# PIC32CX2051MTSH128S1 register map
Vendor: Microchip Technology; Series: PIC32CXMTSH; File version: 0
CPU: CM4 r0p1, little endian, MPU, FPU, 4 interrupt priority bits, 96 interrupts
Registers are 32-bit, read-write, reset 0x0 unless marked. A register's access mark holds for its fields unless they carry their own. Offsets are from the block's base; [hi:lo] are bit positions; {n}, {i} and the like mark numbered series.

## SCB — System Control Block
Base 0xE000ED00
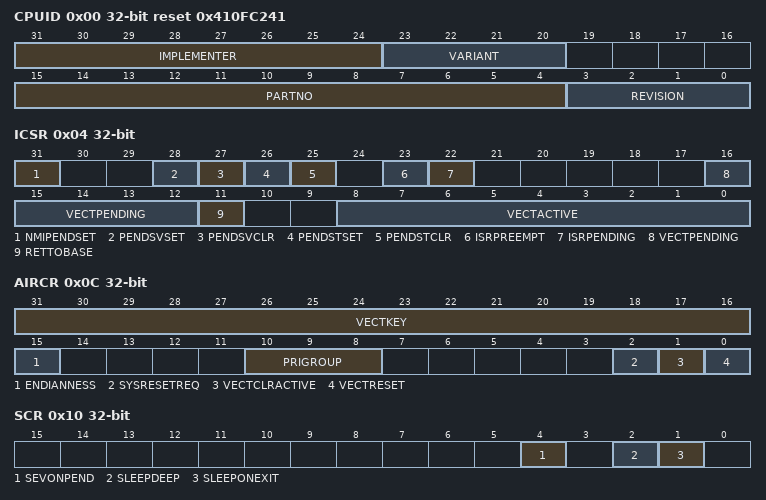
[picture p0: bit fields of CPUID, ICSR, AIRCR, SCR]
0x00 CPUID ro reset 0x410FC241 — CPUID Base Register
  [31:24] IMPLEMENTER — Indicates implementer: 0x41 = ARM
  [23:20] VARIANT — Indicates processor revision: 0x0 = Revision 0
  [15:4] PARTNO — Indicates part number: 0xC24 = Cortex-M4
  [3:0] REVISION — Indicates patch release: 0x1 = Patch 1
0x04 ICSR — Interrupt Control and State Register
  [31] NMIPENDSET — On writes, makes the NMI exception active. On reads, indicates the state of the exception
    0=On writes, has no effect. On reads, NMI is inactive; 1=On writes, make the NMI exception active. On reads, NMI is active
  [28] PENDSVSET — On writes, sets the PendSV exception as pending. On reads, indicates the current state of the exception
    0=On writes, has no effect. On reads, PendSV is not pending; 1=On writes, make PendSV exception pending. On reads, PendSV is pending
  [27] PENDSVCLR — Removes the pending status of the PendSV exception
    0=No effect; 1=Remove pending status
  [26] PENDSTSET — On writes, sets the SysTick exception as pending. On reads, indicates the current state of the exception
    0=On writes, has no effect. On reads, SysTick is not pending; 1=On writes, make SysTick exception pending. On reads, SysTick is pending
  [25] PENDSTCLR — Removes the pending status of the SysTick exception
    0=No effect; 1=Remove pending status
  [23] ISRPREEMPT — Indicates whether a pending exception will be serviced on exit from debug halt state
    0=Will not service; 1=Will service a pending exception
  [22] ISRPENDING — Indicates whether an external interrupt, generated by the NVIC, is pending
  [16:12] VECTPENDING — The exception number of the highest priority pending and enabled interrupt
  [11] RETTOBASE — In Handler mode, indicates whether there is an active exception other than the exception indicated by the current value of the IPSR
    0=There is an active exception other than the exception shown by IPSR; 1=There is no active exception other than any exception shown by IPSR
  [8:0] VECTACTIVE — The exception number of the current executing exception
0x08 VTOR — Vector Table Offset Register
  [31:7] TBLOFF — Bits[31:7] of the vector table address
0x0C AIRCR — Application Interrupt and Reset Control Register
  [31:16] VECTKEY — Vector key
  [15] ENDIANNESS — Indicates the memory system endianness
    0=Little-endian; 1=Big-endian
  [10:8] PRIGROUP — Priority grouping, indicates the binary point position
  [2] SYSRESETREQ — System Reset Request
    0=Do not request a reset; 1=Request reset
  [1] VECTCLRACTIVE — Writing 1 to this bit clears all active state information for fixed and configurable exceptions
  [0] VECTRESET — Writing 1 to this bit causes a local system reset
0x10 SCR — System Control Register
  [4] SEVONPEND — Determines whether an interrupt transition from inactive state to pending state is a wakeup event
    0=Transitions from inactive to pending are not wakeup events; 1=Transitions from inactive to pending are wakeup events
  [2] SLEEPDEEP — Provides a qualifying hint indicating that waking from sleep might take longer
    0=Selected sleep state is not deep sleep; 1=Selected sleep state is deep sleep
  [1] SLEEPONEXIT — Determines whether, on an exit from an ISR that returns to the base level of execution priority, the processor enters a sleep state
    0=Do not enter sleep state; 1=Enter sleep state
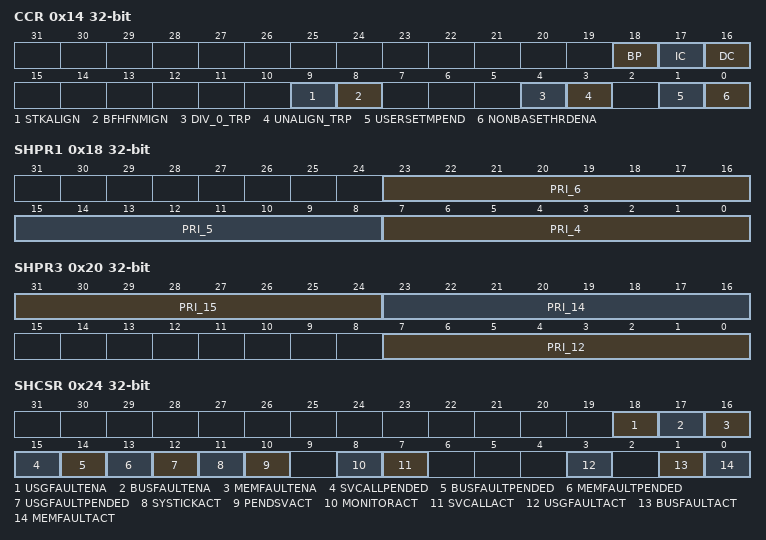
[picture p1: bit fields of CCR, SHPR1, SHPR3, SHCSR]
0x14 CCR — Configuration and Control Register
  [18] BP — Branch prediction enable bit
  [17] IC — Instruction cache enable bit
  [16] DC — Cache enable bit
  [9] STKALIGN — Indicates stack alignment on exception entry
    0=4-byte aligned; 1=8-byte aligned
  [8] BFHFNMIGN — Enables handlers with priority -1 or -2 to ignore data BusFaults caused by load and store instructions.
    0=data bus faults caused by load and store instructions cause a lock-up; 1=handlers running at priority -1 and -2 ignore data bus faults caused by load and store instructions
  [4] DIV_0_TRP — Enables faulting or halting when the processor executes an SDIV or UDIV instruction with a divisor of 0
    0=do not trap divide by 0; 1=trap divide by 0
  [3] UNALIGN_TRP — Enables unaligned access traps
    0=do not trap unaligned halfword and word accesses; 1=trap unaligned halfword and word accesses
  [1] USERSETMPEND — Enables unprivileged software access to the STIR
    0=disable; 1=enable
  [0] NONBASETHRDENA
    0=processor can enter Thread mode only when no exception is active; 1=processor can enter Thread mode from any level under the control of an EXC_RETURN value
0x18 SHPR1 — System Handler Priority Register 1
  [23:16] PRI_6 — Priority of system handler 6, UsageFault
  [15:8] PRI_5 — Priority of system handler 5, BusFault
  [7:0] PRI_4 — Priority of system handler 4, MemManage
0x1C SHPR2 — System Handler Priority Register 2
  [31:24] PRI_11 — Priority of system handler 11, SVCall
0x20 SHPR3 — System Handler Priority Register 3
  [31:24] PRI_15 — Priority of system handler 15, SysTick exception
  [23:16] PRI_14 — Priority of system handler 14, PendSV
  [7:0] PRI_12 — Priority of system handler 12, SysTick
0x24 SHCSR — System Handler Control and State Register
  [18] USGFAULTENA — UsageFault enable
    0=Disable UsageFault; 1=Enable UsageFault
  [17] BUSFAULTENA — BusFault enable
    0=Disable BusFault; 1=Enable BusFault
  [16] MEMFAULTENA — MemManage fault enable
    0=Disable MemManage fault; 1=Enable MemManage fault
  [15] SVCALLPENDED — SVCall pending
    0=SVCall is not pending; 1=SVCall is pending
  [14] BUSFAULTPENDED — BusFault pending
    0=BusFault is not pending; 1=BusFault is pending
  [13] MEMFAULTPENDED — MemManage fault pending
    0=MemManage is not pending; 1=MemManage is pending
  [12] USGFAULTPENDED — UsageFault pending
    0=UsageFault is not pending; 1=UsageFault is pending
  [11] SYSTICKACT — SysTick active
    0=SysTick is not active; 1=SysTick is active
  [10] PENDSVACT — PendSV active
    0=PendSV is not active; 1=PendSV is active
  [8] MONITORACT — Monitor active
    0=Monitor is not active; 1=Monitor is active
  [7] SVCALLACT — SVCall active
    0=SVCall is not active; 1=SVCall is active
  [3] USGFAULTACT — UsageFault active
    0=UsageFault is not active; 1=UsageFault is active
  [1] BUSFAULTACT — BusFault active
    0=BusFault is not active; 1=BusFault is active
  [0] MEMFAULTACT — MemManage fault active
    0=MemManage is not active; 1=MemManage is active
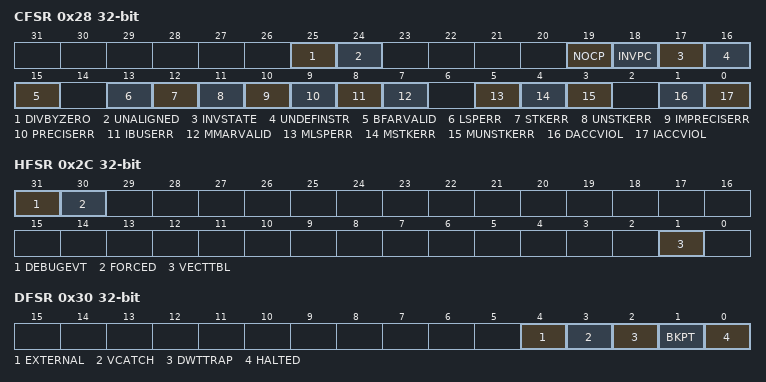
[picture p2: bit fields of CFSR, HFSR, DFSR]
0x28 CFSR — Configurable Fault Status Registers
  [25] DIVBYZERO
    0=No divide by zero fault, or divide by zero trapping not enabled; 1=The processor has executed an SDIV or UDIV instruction with a divisor of 0
  [24] UNALIGNED
    0=No unaligned access fault, or unaligned access trapping not enabled; 1=The processor has made an unaligned memory access
  [19] NOCP
    0=No UsageFault caused by attempting to access a coprocessor; 1=The processor has attempted to access a coprocessor
  [18] INVPC
    0=No invalid PC load UsageFault; 1=The processor has attempted an illegal load of EXC_RETURN to the PC
  [17] INVSTATE
    0=No invalid state UsageFault; 1=The processor has attempted to execute an instruction that makes illegal use of the EPSR
  [16] UNDEFINSTR
    0=No undefined instruction UsageFault; 1=The processor has attempted to execute an undefined instruction
  [15] BFARVALID
    0=Value in BFAR is not a valid fault address; 1=BFAR holds a valid fault address
  [13] LSPERR
    0=No bus fault occurred during floating-point lazy state preservation; 1=A bus fault occurred during floating-point lazy state preservation
  [12] STKERR
    0=No stacking fault; 1=Stacking for an exception entry has caused one or more BusFaults
  [11] UNSTKERR
    0=No unstacking fault; 1=Unstack for an exception return has caused one or more BusFaults
  [10] IMPRECISERR
    0=No imprecise data bus error; 1=A data bus error has occurred, but the return address in the stack frame is not related to the instruction that caused the error
  [9] PRECISERR
    0=No precise data bus error; 1=A data bus error has occurred, and the PC value stacked for the exception return points to the instruction that caused the fault
  [8] IBUSERR
    0=No instruction bus error; 1=Instruction bus error
  [7] MMARVALID
    0=Value in MMAR is not a valid fault address; 1=MMAR holds a valid fault address
  [5] MLSPERR
    0=No MemManage fault occurred during floating-point lazy state preservation; 1=A MemManage fault occurred during floating-point lazy state preservation
  [4] MSTKERR
    0=No stacking fault; 1=Stacking for an exception entry has caused one or more access violations
  [3] MUNSTKERR
    0=No unstacking fault; 1=Unstack for an exception return has caused one or more access violations
  [1] DACCVIOL — Data access violation status
    0=No data access violation fault; 1=The processor attempted a load or store at a location that does not permit the operation
  [0] IACCVIOL — Instruction fetch access violation status
    0=No instruction access violation fault; 1=The processor attempted an instruction fetch from a location that does not permit execution
0x2C HFSR — HardFault Status register
  [31] DEBUGEVT — Indicates when a Debug event has occurred
  [30] FORCED — Indicates that a fault with configurable priority has been escalated to a HardFault exception
    0=No forced HardFault; 1=Forced HardFault
  [1] VECTTBL — Indicates when a fault has occurred because of a vector table read error on exception processing
    0=No BusFault on vector table read; 1=BusFault on vector table read
0x30 DFSR — Debug Fault Status Register
  [4] EXTERNAL — Indicates a debug event generated because of the assertion of an external debug request
    0=No EDBGRQ debug event; 1=EDBGRQ debug event
  [3] VCATCH — Indicates triggering of a Vector catch
    0=No Vector catch triggered; 1=Vector catch triggered
  [2] DWTTRAP — Indicates a debug event generated by the DWT
    0=No current debug events generated by the DWT; 1=At least one current debug event generated by the DWT
  [1] BKPT — Indicates a debug event generated by BKPT instruction execution or a breakpoint match in FPB
    0=No current breakpoint debug event; 1=At least one current breakpoint debug event
  [0] HALTED — Indicates a debug event generated by either HALT or STEP
    0=No active halt request debug event; 1=Halt request debug event active
0x34 MMFAR — MemManage Address Register
  [31:0] ADDRESS — Address of MemManage fault location
0x38 BFAR — BusFault Address Register
  [31:0] ADDRESS — Address of the BusFault location
0x3C AFSR — Auxiliary Fault Status Register
  [31:0] AUXFAULT — Latched version of the AUXFAULT inputs
{0x40+4i} PFR[{i}] (i=0..1) ro — Processor Feature Register
0x48 DFR ro — Debug Feature Register
0x4C AFR ro — Auxiliary Feature Register
{0x50+4i} MMFR[{i}] (i=0..3) ro — Memory Model Feature Register
{0x60+4i} ISAR[{i}] (i=0..4) ro — Instruction Set Attributes Register
0x88 CPACR — Coprocessor Access Control Register
